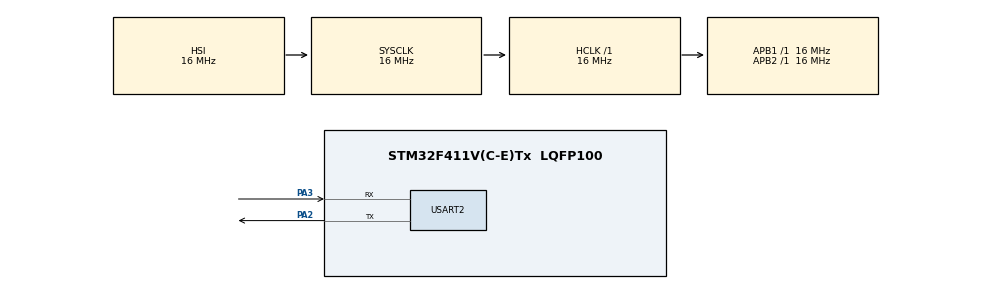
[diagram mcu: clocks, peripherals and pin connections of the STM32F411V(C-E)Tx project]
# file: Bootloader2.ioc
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Dma.Request0=USART2_RX
Dma.USART2_RX.0.Direction=DMA_PERIPH_TO_MEMORY
Dma.USART2_RX.0.FIFOMode=DMA_FIFOMODE_DISABLE
Dma.USART2_RX.0.Instance=DMA1_Stream5
Dma.USART2_RX.0.MemDataAlignment=DMA_MDATAALIGN_BYTE
Dma.USART2_RX.0.MemInc=DMA_MINC_ENABLE
Dma.USART2_RX.0.Mode=DMA_NORMAL
Dma.USART2_RX.0.PeriphDataAlignment=DMA_PDATAALIGN_BYTE
Dma.USART2_RX.0.PeriphInc=DMA_PINC_DISABLE
Dma.USART2_RX.0.Priority=DMA_PRIORITY_LOW
Mcu.Family=STM32F4
Mcu.Name=STM32F411V(C-E)Tx
Mcu.Package=LQFP100
NVIC.DMA1_Stream5_IRQn=true\:0\:0\:false\:false\:true\:false\:true\:true
NVIC.PriorityGroup=NVIC_PRIORITYGROUP_4
PA13.Mode=Serial_Wire
PA13.Signal=SYS_JTMS-SWDIO
PA14.Mode=Serial_Wire
PA14.Signal=SYS_JTCK-SWCLK
PA2.Mode=Asynchronous
PA2.Signal=USART2_TX
PA3.Mode=Asynchronous
PA3.Signal=USART2_RX
ProjectManager.HeapSize=0x200
ProjectManager.StackSize=0x400
ProjectManager.TargetToolchain=STM32CubeIDE
RCC.AHBFreq_Value=16000000
RCC.APB1Freq_Value=16000000
RCC.APB2Freq_Value=16000000
RCC.CortexFreq_Value=16000000
RCC.HSE_VALUE=25000000
RCC.HSI_VALUE=16000000
RCC.LSE_VALUE=32768
RCC.SYSCLKFreq_VALUE=16000000
RCC.VCOOutputFreq_Value=192000000
USART2.VirtualMode=VM_ASYNC
board=custom

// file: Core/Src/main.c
/* USER CODE BEGIN Header */
/**
  ******************************************************************************
  * @file           : main.c
  * @brief          : Main program body
  ******************************************************************************
  * @attention
  *
  * Copyright (c) 2024 STMicroelectronics.
  * All rights reserved.
  *
  * This software is licensed under terms that can be found in the LICENSE file
  * in the root directory of this software component.
  * If no LICENSE file comes with this software, it is provided AS-IS.
  *
  ******************************************************************************
  */
/* USER CODE END Header */
#include "main.h"

/* USER CODE BEGIN Includes */
#include <string.h>
#include <stdio.h>
/* USER CODE END Includes */

UART_HandleTypeDef huart2;
DMA_HandleTypeDef hdma_usart2_rx;

void SystemClock_Config(void);
static void MX_GPIO_Init(void);
static void MX_DMA_Init(void);
static void MX_USART2_UART_Init(void);

/* USER CODE BEGIN 0 */
void printf_msg(char* msg)
{
	 HAL_UART_Transmit(&huart2, (uint8_t*)msg, strlen(msg), HAL_MAX_DELAY);
}
/* USER CODE END 0 */

int main(void)
{

  /* MCU Configuration--------------------------------------------------------*/

  /* Reset of all peripherals, Initializes the Flash interface and the Systick. */
  HAL_Init();

  /* Configure the system clock */
  SystemClock_Config();

  /* Initialize all configured peripherals */
  MX_GPIO_Init();
  MX_DMA_Init();
  MX_USART2_UART_Init();
  /* USER CODE BEGIN 2 */
  char* Data = (char*) 0x0800C000;
    printf_msg("BOOTLOADER\r\n");
    if(strstr(Data,"new_fw")!=0)
    {

  	  printf_msg("Detect new firmware\r\n");
  	  printf_msg("Preparing update...\r\n");
  	  HAL_FLASH_Unlock();
  	  FLASH_EraseInitTypeDef sector5 = {
  			  .TypeErase = FLASH_TYPEPROGRAM_BYTE,
  			  .Banks = FLASH_BANK_1,
  			  .Sector = FLASH_SECTOR_5,
  			  .NbSectors = 1,
  			  .VoltageRange = FLASH_VOLTAGE_RANGE_1,
  	  };
  	  uint32_t sector_err = 0;
  	  HAL_FLASHEx_Erase(&sector5, &sector_err);
  	  printf_msg("Installing...\r\n");
  	  char* new_fw_update = (char*)0x08040000;
  	  for(int i = 0 ; i < 131072;i++)
  	  {
  		  HAL_FLASH_Program(FLASH_TYPEPROGRAM_BYTE, 0x08020000 +i, new_fw_update[i]);
  	  }
  	  printf_msg("Done!\r\n");
  	  FLASH_EraseInitTypeDef sector3 ={
  			  .TypeErase = FLASH_TYPEPROGRAM_BYTE,
  			  .Banks = FLASH_BANK_1,
  			  .NbSectors = 1,
  			  .Sector = FLASH_SECTOR_3,
  			  .VoltageRange = FLASH_VOLTAGE_RANGE_1,
  	  };
  	  HAL_FLASHEx_Erase(&sector3, &sector_err);
  	  char* data = (char*)"Installer but not yet veryfied";
  	  for(int i = 0; i < strlen(data)+1;i++)
  	  {
  		  HAL_FLASH_Program(FLASH_TYPEPROGRAM_BYTE, 0x0800C000 +i, data[i]);
  	  }

    }
    else  if(strstr(Data,"Installer but not yet veryfied")!=0)
    {
  	  uint32_t sector_err = 0;
  	  HAL_FLASH_Unlock();
  	  FLASH_EraseInitTypeDef sector5 = {
  			  .TypeErase=FLASH_TYPEPROGRAM_BYTE,
  			  .Banks = FLASH_BANK_1,
  			  .NbSectors=1,
  			  .Sector=FLASH_SECTOR_5,
  			  .VoltageRange=FLASH_VOLTAGE_RANGE_1,
  	  };
  	  HAL_FLASHEx_Erase(&sector5, &sector_err);
  	  char* Backup_fw = (char*)0x08060000;
  	  for(int i = 0; i < 131072; i++)
  	  {
  		  HAL_FLASH_Program(FLASH_TYPEPROGRAM_BYTE, 0x08020000 + i, Backup_fw[i]);
  	  }

  	  printf_msg("Backup fw success veryfied\r\n");

    }

    printf_msg("Jump to FW\r\n");

    void(*main_program)();
    uint32_t* vectortable = (uint32_t*)0x08020000;
    main_program = (void(*)())(vectortable[1]);
    main_program();
  /* USER CODE END 2 */

  /* Infinite loop */
  while (1)
  {

  }
}

void SystemClock_Config(void)
{
  RCC_OscInitTypeDef RCC_OscInitStruct = {0};
  RCC_ClkInitTypeDef RCC_ClkInitStruct = {0};

  /** Configure the main internal regulator output voltage
  */
  __HAL_RCC_PWR_CLK_ENABLE();
  __HAL_PWR_VOLTAGESCALING_CONFIG(PWR_REGULATOR_VOLTAGE_SCALE1);

  /** Initializes the RCC Oscillators according to the specified parameters
  * in the RCC_OscInitTypeDef structure.
  */
  RCC_OscInitStruct.OscillatorType = RCC_OSCILLATORTYPE_HSI;
  RCC_OscInitStruct.HSIState = RCC_HSI_ON;
  RCC_OscInitStruct.HSICalibrationValue = RCC_HSICALIBRATION_DEFAULT;
  RCC_OscInitStruct.PLL.PLLState = RCC_PLL_NONE;
  if (HAL_RCC_OscConfig(&RCC_OscInitStruct) != HAL_OK)
  {
    Error_Handler();
  }

  /** Initializes the CPU, AHB and APB buses clocks
  */
  RCC_ClkInitStruct.ClockType = RCC_CLOCKTYPE_HCLK|RCC_CLOCKTYPE_SYSCLK
                              |RCC_CLOCKTYPE_PCLK1|RCC_CLOCKTYPE_PCLK2;
  RCC_ClkInitStruct.SYSCLKSource = RCC_SYSCLKSOURCE_HSI;
  RCC_ClkInitStruct.AHBCLKDivider = RCC_SYSCLK_DIV1;
  RCC_ClkInitStruct.APB1CLKDivider = RCC_HCLK_DIV1;
  RCC_ClkInitStruct.APB2CLKDivider = RCC_HCLK_DIV1;

  if (HAL_RCC_ClockConfig(&RCC_ClkInitStruct, FLASH_LATENCY_0) != HAL_OK)
  {
    Error_Handler();
  }
}

static void MX_USART2_UART_Init(void)
{

  huart2.Instance = USART2;
  huart2.Init.BaudRate = 115200;
  huart2.Init.WordLength = UART_WORDLENGTH_8B;
  huart2.Init.StopBits = UART_STOPBITS_1;
  huart2.Init.Parity = UART_PARITY_NONE;
  huart2.Init.Mode = UART_MODE_TX_RX;
  huart2.Init.HwFlowCtl = UART_HWCONTROL_NONE;
  huart2.Init.OverSampling = UART_OVERSAMPLING_16;
  if (HAL_UART_Init(&huart2) != HAL_OK)
  {
    Error_Handler();
  }

}

static void MX_DMA_Init(void)
{

  /* DMA controller clock enable */
  __HAL_RCC_DMA1_CLK_ENABLE();

  /* DMA interrupt init */
  /* DMA1_Stream5_IRQn interrupt configuration */
  HAL_NVIC_SetPriority(DMA1_Stream5_IRQn, 0, 0);
  HAL_NVIC_EnableIRQ(DMA1_Stream5_IRQn);

}

static void MX_GPIO_Init(void)
{

  /* GPIO Ports Clock Enable */
  __HAL_RCC_GPIOA_CLK_ENABLE();

}

void Error_Handler(void)
{
  __disable_irq();
  while (1)
  {
  }
}
